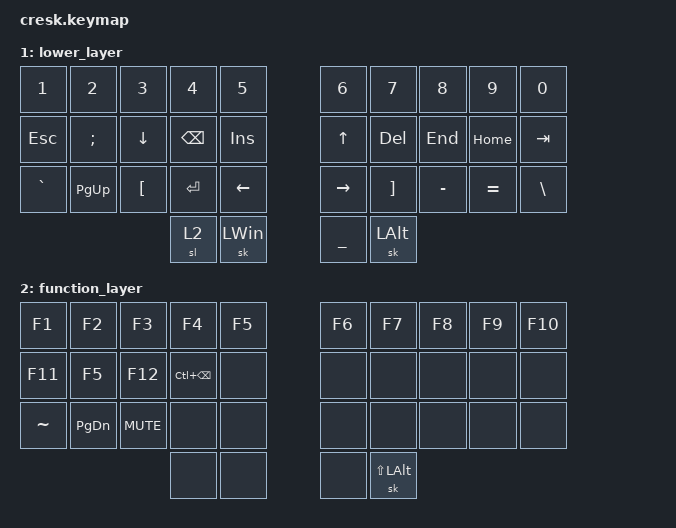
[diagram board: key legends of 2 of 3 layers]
/*
 * Copyright (c) 2022 The ZMK Contributors
 *
 * SPDX-License-Identifier: MIT
 */

#include <behaviors.dtsi>
#include <dt-bindings/zmk/keys.h>

&sk {
    release-after-ms = <200>;
};

&sl {
    release-after-ms = <200>;
};

/ {
    behaviors {
        td0: tap_dance_0 {
            compatible = "zmk,behavior-tap-dance";
            label = "TAP_DANCE_0";
            #binding-cells = <0>;
            tapping-term-ms = <200>;
            bindings = <&sk LSHIFT>, <&caps_word>;
        };
    };

    keymap {
        compatible = "zmk,keymap";

        default_layer {
            bindings = <
&kp F &kp L &kp H &kp V &kp Z &kp C &kp W &kp U &kp O &kp Y
&kp S &kp R &kp N &kp T &kp K &kp P &kp D &kp E &kp A &kp I
&kp X &kp J &kp B &kp M &kp Q &kp SQT &kp G &kp COMMA &kp DOT &kp FSLH
&sl 1 &sk LCTRL &kp SPACE &td0
&kp F &kp L &kp H &kp V
&kp S &kp R &kp N &kp T
&kp X &kp J &kp B &kp M
            >;

            sensor-bindings = <&inc_dec_kp C_VOL_UP C_VOL_DN>;
        }
;
        lower_layer {
            bindings = <
&kp N1       &kp N2    &kp N3    &kp N4       &kp N5   &kp N6    &kp N7   &kp N8    &kp N9    &kp N0
&kp ESC      &kp SEMI   &kp DOWN  &kp BSPC     &kp INS &kp UP &kp DEL  &kp END   &kp HOME  &kp TAB
&kp GRAVE    &kp PG_UP &kp LBKT  &kp RET      &kp LEFT  &kp RIGHT    &kp RBKT &kp MINUS &kp EQUAL &kp BSLH
&sl 2     &sk LWIN  &kp UNDERSCORE &sk LALT
            >;
        };

        function_layer {
            bindings = <
&kp F1       &kp F2    &kp F3     &kp F4       &kp F5   &kp F6    &kp F7   &kp F8    &kp F9    &kp F10
&kp F11      &kp F5    &kp F12    &kp LC(BSPC) &none    &none     &none    &none     &none     &none
&kp TILDE    &kp PG_DN &kp C_MUTE &none        &none    &none     &none    &none     &none     &none
&none        &none     &none      &sk LS(LALT)
            >;
        };
    };
};
